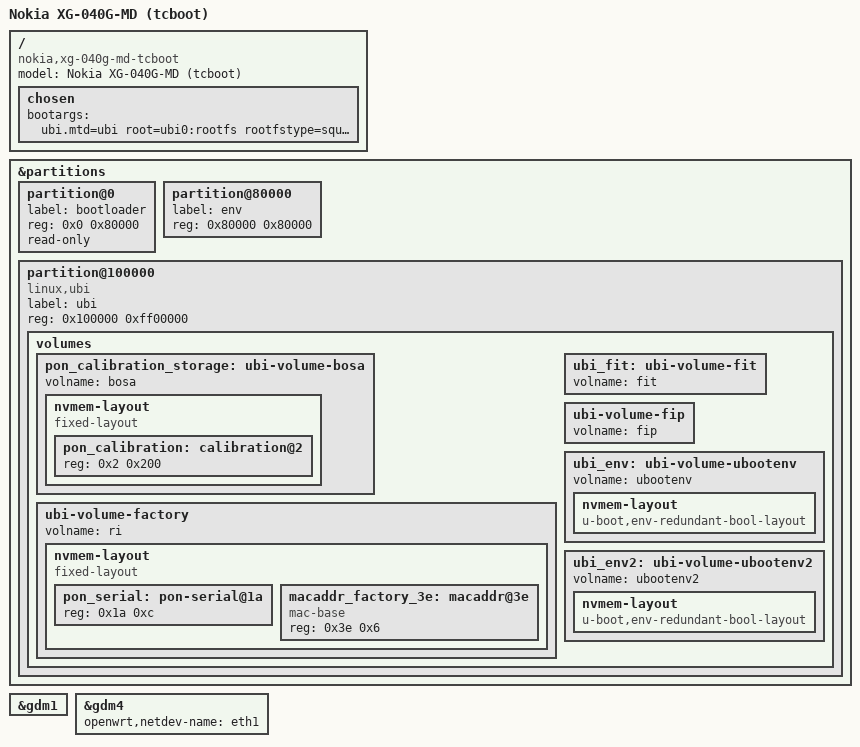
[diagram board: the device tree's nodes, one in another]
// SPDX-License-Identifier: GPL-2.0-only OR MIT

#include "an7581-nokia_xg-040g-md-common.dtsi"

/ {
	model = "Nokia XG-040G-MD (tcboot)";
	compatible = "nokia,xg-040g-md-tcboot", "airoha,an7581",
		     "airoha,en7581";

	chosen {
		bootargs = "ubi.mtd=ubi root=ubi0:rootfs rootfstype=squashfs ro rootwait console=ttyS0,115200 earlycon";
	};
};

&partitions {
	partition@0 {
		label = "bootloader";
		reg = <0x0 0x80000>;
		read-only;
	};

	partition@80000 {
		label = "env";
		reg = <0x80000 0x80000>;
	};

	partition@100000 {
		label = "ubi";
		reg = <0x100000 0xff00000>;
		compatible = "linux,ubi";

		volumes {
			pon_calibration_storage: ubi-volume-bosa {
				volname = "bosa";

				nvmem-layout {
					compatible = "fixed-layout";

					#address-cells = <1>;
					#size-cells = <1>;

					/* The UBI volume retains its header while NVMEM exposes 512-byte BOB. */
					pon_calibration: calibration@2 {
						reg = <0x2 0x200>;
					};
				};
			};

			ubi-volume-factory {
				volname = "ri";

				nvmem-layout {
					compatible = "fixed-layout";

					#address-cells = <1>;
					#size-cells = <1>;

					/* RI offset 0x1a stores VEND plus eight hexadecimal VSSN characters. */
					pon_serial: pon-serial@1a {
						reg = <0x1a 0xc>;
					};

					macaddr_factory_3e: macaddr@3e {
						compatible = "mac-base";
						reg = <0x3e 0x6>;
						#nvmem-cell-cells = <1>;
					};
				};
			};

			ubi_fit: ubi-volume-fit {
				volname = "fit";
			};

			ubi-volume-fip {
				volname = "fip";
			};

			ubi_env: ubi-volume-ubootenv {
				volname = "ubootenv";
			};

			ubi_env2: ubi-volume-ubootenv2 {
				volname = "ubootenv2";
			};
		};
	};
};

&gdm1 {
	/delete-property/ nvmem-cell-names;
	/delete-property/ nvmem-cells;
};

&gdm4 {
	openwrt,netdev-name = "eth1";

	/delete-property/ nvmem-cell-names;
	/delete-property/ nvmem-cells;
};

&ubi_env {
	nvmem-layout {
		compatible = "u-boot,env-redundant-bool-layout";
	};
};

&ubi_env2 {
	nvmem-layout {
		compatible = "u-boot,env-redundant-bool-layout";
	};
};
